AUTOSAR XML (schema 00047)
package /DemoApplication/SwComponentTypes
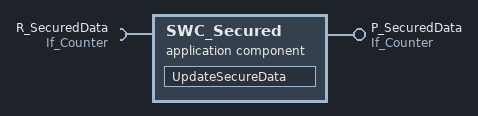
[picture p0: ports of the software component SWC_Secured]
  application sw component type SWC_Secured
    provide port P_SecuredData: provided-interface=If_Counter
    require port R_SecuredData: required-interface=If_Counter
    behavior IB_SWC_Secured: handle-termination-and-restart=NO-SUPPORT
      data received event SecuredDataReceived: start-on-event=UpdateSecureData, data=R_SecuredData.CounterValue
      runnable UpdateSecureData: symbol=SWC_Secured_Data_Received
        data-receive-point-by-arguments:
          access SecureDataIn: accessed-variable=R_SecuredData.CounterValue
        data-write-access:
          access SecureDataOut: accessed-variable=P_SecuredData.CounterValue
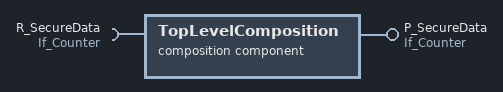
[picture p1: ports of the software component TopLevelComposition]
  composition sw component type TopLevelComposition
    provide port P_SecureData: provided-interface=If_Counter
    require port R_SecureData: required-interface=If_Counter
    component SWC_Secured: type=SWC_Secured
package /DemoApplication/SwcImplementations
  swc implementation Impl_SWC_Secured: programming-language=C, sw-version=1.0.0, vendor-id=1, behavior=IB_SWC_Secured
    code-descriptors:
      code SRC: artifact-descriptors=autosar-engineering-object={short-label=EngObject, category=SWSRC}
    resource consumption Resources
      memory section RTE_START_SEC_APPL_CODE: sw-addrmethod=CODE, symbol=CODE
